# MINI51DE_v1 register map
File version: 1.0
Registers are 32-bit, read-write, reset 0x0 unless marked. A register's access mark holds for its fields unless they carry their own. Offsets are from the block's base; [hi:lo] are bit positions; {n}, {i} and the like mark numbered series.

## FMC — FMC Register Map
Base 0x5000C000
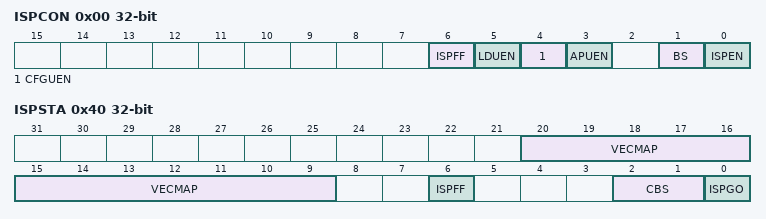
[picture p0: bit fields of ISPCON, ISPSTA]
0x00 ISPCON — ISP Control Register
  [6] ISPFF — ISP Fail Flag (Write Protect). This bit is set by hardware when a triggered ISP meets any of the following conditions: (3) User Configuration is erased/programmed when CFGUEN is 0. (4) Destination address is illegal, such as over an available range. Note: Write 1 to clear this bit to 0.
  [5] LDUEN — LDROM Update Enable Control (Write Protect)
    0=LDROM cannot be updated; 1=LDROM can be updated when the MCU runs in APROM
  [4] CFGUEN — CONFIG Update Enable Control (Write Protect). Writing this bit to 1 enables software to update CONFIG value by ISP register control procedure regardless of program code is running in APROM or LDROM.
    0=ISP update User Configuration Disabled; 1=ISP update User Configuration Enabled
  [3] APUEN — APROM Update Enable Control (Write Protect)
    0=APROM cannot be updated when chip runs in APROM; 1=APROM can be updated when chip runs in APROM
  [1] BS — Boot Select (Write Protect). Set/clear this bit to select next booting from LDROM/APROM, respectively. This bit also functions as chip booting status flag, which can be used to check where chip booted from. This bit is initiated with the inversed value of CBS in CONFIG0 after any reset is happened except CPU reset (RSTS_CPU is 1) or system reset (RSTS_SYS) is happened.
    0=Boot from APROM; 1=Boot from LDROM
  [0] ISPEN — ISP Enable Control (Write Protect). Set this bit to enable ISP function.
    0=ISP function Disabled; 1=ISP function Enabled
0x04 ISPADR — ISP Address Register
  [31:0] ISPADR — ISP Address. The NuMicro Mini51TM series supports word program only. ISPADR[1:0] must be kept 00 for ISP operation.
0x08 ISPDAT — ISP Data Register
  [31:0] ISPDAT — ISP Data. Write data to this register before ISP program operation. Read data from this register after ISP read operation.
0x0C ISPCMD — ISP Command Register
  [5:0] ISPCMD — ISP Command. ISP commands are shown below:
    0=Read; 4=Read Unique ID; 11=Read Company ID (0xDA); 33=Program; 34=Page Erase; 46=Set Vector Page Re-Map
0x10 ISPTRG — ISP Trigger Register
  [0] ISPGO — ISP Start Trigger (Write Protect). Write 1 to start ISP operation and this bit will be cleared to 0 by hardware automatically when ISP operation is finished.
    0=ISP operation is finished; 1=ISP operation is progressed
0x14 DFBA ro reset 0x3800 — Data Flash Start Address
  [31:0] DFBA — Data Flash Base Address. This register indicates Data Flash start address. It is a read only register. The Data Flash start address is defined by user. Since on chip flash erase unit is 512 bytes, it is mandatory to keep bit 8-0 as 0.
0x40 ISPSTA — ISP Status Register
  [20:9] VECMAP ro — Vector Page Mapping Address (Read Only). The current flash address space 0x0000_0000~0x0000_01FF is mapping to address {VECMAP[11:0], 9'h000} ~ {VECMAP[11:0], 9'h1FF}.
  [6] ISPFF — ISP Fail Flag (Write Protect). This bit is set by hardware when a triggered ISP meets any of the following conditions: (3) User Configuration is erased/programmed when CFGUEN is 0. (4) Destination address is illegal, such as over an available range. Write 1 to clear. Note: This bit functions the same as ISPCON bit 6.
  [2:1] CBS ro — Config Boot Selection (Read Only). This is a mirror of CBS in CONFIG0.
  [0] ISPGO ro — ISP Start Trigger (Read Only). Write 1 to start ISP operation and this bit will be cleared to 0 by hardware automatically when ISP operation is finished. Note: This bit is the same with ISPTRG bit 0.
    0=ISP operation is finished; 1=ISP operation is progressed

## WDT — WDT Register Map
Base 0x40004000
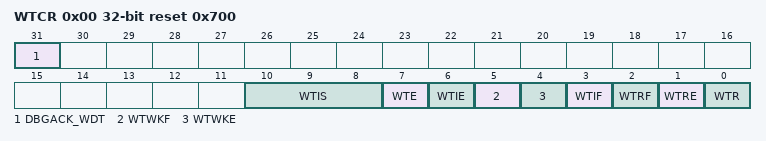
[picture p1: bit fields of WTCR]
0x00 WTCR reset 0x700 — Watchdog Timer Control Register
  [31] DBGACK_WDT — ICE Debug Mode Acknowledge Disable Control (Write Protect). WDT up counter will keep going no matter CPU is hanging by ICE or not.
    0=ICE debug mode acknowledgement effects WDT counting; 1=ICE debug mode acknowledgement Disabled
  [10:8] WTIS — Watchdog Timer Interval Selection. These three bits select the time-out interval for the Watchdog Timer.
    0=24 * TWDT; 1=26 * TWDT; 2=28 * TWDT; 3=210 * TWDT; 4=212 * TWDT; 5=214 * TWDT; 6=216 * TWDT; 7=218 * TWDT
  [7] WTE — Watchdog Timer Enable Control (Write Protect)
    0=WDT Disabled. (This action will reset the internal up counter value.); 1=WDT Enabled
  [6] WTIE — Watchdog Timer Time-out Interrupt Enable Control (Write Protect). If this bit is enabled, the WDT time-out interrupt signal is generated and inform to CPU.
    0=WDT time-out interrupt Disabled; 1=WDT time-out interrupt Enabled
  [5] WTWKF — Watchdog Timer Time-out Wake-up Flag. This bit indicates the interrupt wake-up flag status of WDT. Note: This bit is cleared by writing 1 to it.
    0=WDT does not cause chip wake-up; 1=Chip wake-up from Idle or Power-down mode if WDT time-out interrupt signal generated
  [4] WTWKE — Watchdog Timer Time-out Wake-up Function Control (Write Protect). If this bit is set to 1, while WTIF is generated to 1 and WTIE enabled, the WDT time-out interrupt signal will generate a wake-up trigger event to chip. Note: Chip can be woken-up by WDT time-out interrupt signal generated only if WDT clock source is selected to 10 kHz oscillator.
    0=Wake-up trigger event Disabled if WDT time-out interrupt signal generated; 1=Wake-up trigger event Enabled if WDT time-out interrupt signal generated
  [3] WTIF — Watchdog Timer Time-out Interrupt Flag. This bit will be set to 1 while WDT up counter value reaches the selected WDT time-out interval. Note: This bit is cleared by writing 1 to it.
    0=WDT time-out interrupt did not occur; 1=WDT time-out interrupt occurred
  [2] WTRF — Watchdog Timer Time-out Reset Flag. This bit indicates the system has been reset by WDT time-out reset or not. Note: This bit is cleared by writing 1 to it.
    0=WDT time-out reset did not occur; 1=WDT time-out reset occurred
  [1] WTRE — Watchdog Timer Time-out Reset Enable Control (Write Protect). Setting this bit will enable the WDT time-out reset function if the WDT up counter value has not been cleared after the specific WDT reset delay period (1024 * TWDT) expires.
    0=WDT time-out reset function Disabled; 1=WDT time-out reset function Enabled
  [0] WTR — Reset Watchdog Timer Up Counter (Write Protect). Note: This bit will be automatically cleared by hardware.
    0=No effect; 1=Reset the internal 18-bit WDT up counter value
